# ATtiny1634 device description
Architecture: AVR8; Family: tinyAVR
Registers are 8-bit, access not given, no defined reset value unless marked. A register's access mark holds for its fields unless they carry their own. Offsets are from the block's base; [hi:lo] are bit positions; {n}, {i} and the like mark numbered series.

## PORTB — I/O Port
Instances: PORTB 0x00
0x2B PINB bits used 3:0 — Port B Data register
0x2C DDRB bits used 3:0 — Data Direction Register, Port B
0x2D PORTB bits used 3:0 — Input Pins, Port B
0x2E PUEB — Pull-up Enable Control Register
  [3:0] PUEB — Pull-up Enable Control bit
0x33 PORTCR — Port Control Register
  [1] BBMB — Break-Before-Make Mode Enable

## PORTC — I/O Port
Instances: PORTC 0x00
0x27 PINC bits used 5:0 — Port C Input Pins
0x28 DDRC bits used 5:0 — Data Direction Register, Port C
0x29 PORTC bits used 5:0 — Port C Data Register
0x2A PUEC — Pull-up Enable Control Register
  [5:0] PUEC — Pull-up Enable Control bit
0x33 PORTCR — Port Control Register
  [2] BBMC — Break-Before-Make Mode Enable

## PORTA — I/O Port
Instances: PORTA 0x00
0x2F PINA — Port A Input Pins
0x30 DDRA — Data Direction Register, Port A
0x31 PORTA — Port A Data Register
0x32 PUEA — Pull-up Enable Control Register
  [7:0] PUEA — Pull-up Enable Control bit
0x33 PORTCR — Port Control Register
  [0] BBMA — Break-Before-Make Mode Enable

## ADC — Analog-to-Digital Converter
Instances: ADC 0x00
0x20 ADC 16-bit — ADC Data Register Bytes
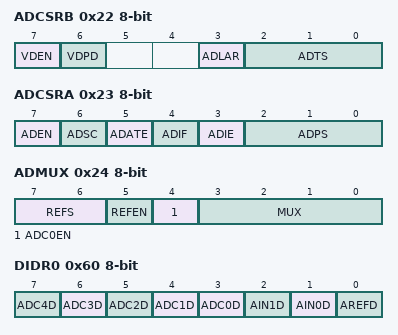
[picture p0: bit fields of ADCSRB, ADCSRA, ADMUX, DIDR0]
0x22 ADCSRB — ADC Control and Status Register B
  [7] VDEN
  [6] VDPD
  [3] ADLAR
  [2:0] ADTS — ADC Auto Trigger Sources
    0=FREE_RUNNING_MODE; 1=ANALOG_COMPARATOR; 2=EXTERNAL_INTERRUPT_REQUEST_0; 3=TIMER_COUNTER0_COMPARE_MATCH_A; 4=TIMER_COUNTER0_OVERFLOW; 5=TIMER_COUNTER1_COMPARE_MATCH_B; 6=TIMER_COUNTER1_OVERFLOW; 7=TIMER_COUNTER1_CAPTURE_EVENT
0x23 ADCSRA — The ADC Control and Status register
  [7] ADEN — ADC Enable
  [6] ADSC — ADC Start Conversion
  [5] ADATE — ADC Auto Trigger Enable
  [4] ADIF — ADC Interrupt Flag
  [3] ADIE — ADC Interrupt Enable
  [2:0] ADPS — ADC Prescaler Select Bits
    0=2; 1=2; 2=4; 3=8; 4=16; 5=32; 6=64; 7=128
0x24 ADMUX — The ADC multiplexer Selection Register
  [7:6] REFS — Reference Selection Bit
  [5] REFEN
  [4] ADC0EN
  [3:0] MUX — Analog Channel and Gain Selection Bits
0x60 DIDR0 — Digital Input Disable Register 0
  [n+3] ADC{n}D (n=1..4) — ADC{n} Digital input Disable
  [3] ADC0D — ADC0 Digital Input Disable
  [2] AIN1D — AIN1 Digital input Disable
  [1] AIN0D — AIN0 Digital input Disable
  [0] AREFD — AREF Digital input Disable
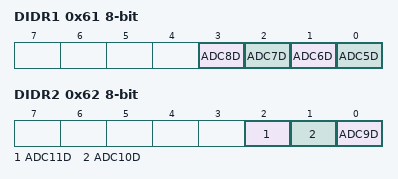
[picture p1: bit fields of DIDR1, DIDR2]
0x61 DIDR1 — Digital Input Disable Register 1
  [3] ADC8D — ADC8 Digital Input Disable
  [2] ADC7D — ADC7 Digital input Disable
  [1] ADC6D — ADC6 Digital input Disable
  [0] ADC5D — ADC5 Digital input Disable
0x62 DIDR2 — Digital Input Disable Register 2
  [2] ADC11D — ADC11 Digital input Disable
  [1] ADC10D — ADC10 Digital input Disable
  [0] ADC9D — ADC9 Digital input Disable

## AC — Analog Comparator
Instances: AC 0x00
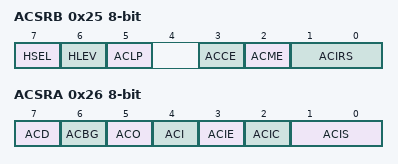
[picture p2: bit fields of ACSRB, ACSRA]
0x25 ACSRB — Analog Comparator Control And Status Register B
  [7] HSEL — Hysteresis Select
  [6] HLEV — Hysteresis Level
  [5] ACLP
  [3] ACCE
  [2] ACME — Analog Comparator Multiplexer Enable
  [1:0] ACIRS
0x26 ACSRA — Analog Comparator Control And Status Register A
  [7] ACD — Analog Comparator Disable
  [6] ACBG — Analog Comparator Bandgap Select
  [5] ACO — Analog Compare Output
  [4] ACI — Analog Comparator Interrupt Flag
  [3] ACIE — Analog Comparator Interrupt Enable
  [2] ACIC — Analog Comparator Input Capture Enable
  [1:0] ACIS — Analog Comparator Interrupt Mode Select bits
    0=INTERRUPT_ON_TOGGLE; 2=INTERRUPT_ON_FALLING_EDGE; 3=INTERRUPT_ON_RISING_EDGE

## EEPROM
Instances: EEPROM 0x00
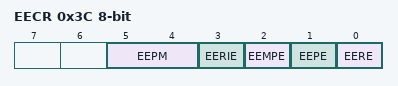
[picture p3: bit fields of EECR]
0x3C EECR — EEPROM Control Register
  [5:4] EEPM — EEPROM Programming Mode Bits
    0=ERASE_AND_WRITE_IN_ONE_OPERATION; 1=ERASE_ONLY; 2=WRITE_ONLY
  [3] EERIE — EEProm Ready Interrupt Enable
  [2] EEMPE — EEPROM Master Write Enable
  [1] EEPE — EEPROM Write Enable
  [0] EERE — EEPROM Read Enable
0x3D EEDR — EEPROM Data Register
0x3E EEAR 16-bit bits used 8:0 — EEPROM Read/Write Access
